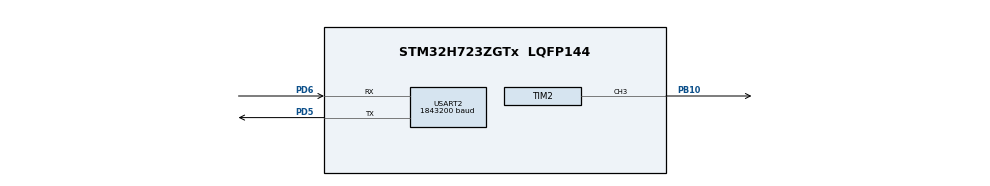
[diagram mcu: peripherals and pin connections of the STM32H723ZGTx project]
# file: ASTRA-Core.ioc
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CORTEX_M7.default_mode_Activation=1
Mcu.Family=STM32H7
Mcu.Name=STM32H723ZGTx
Mcu.Package=LQFP144
NUCLEO-H723ZG.BUTTON=1
NUCLEO-H723ZG.LD1=true
NUCLEO-H723ZG.LD2=true
NUCLEO-H723ZG.LD3=true
NUCLEO-H723ZG.VCP=true
NVIC.EXTI15_10_IRQn=true\:0\:0\:false\:false\:true\:false\:true\:true
NVIC.PriorityGroup=NVIC_PRIORITYGROUP_4
NVIC.USART2_IRQn=true\:0\:0\:false\:false\:true\:true\:true\:true
PA13(JTMS/SWDIO).GPIO_Label=SWDIO
PA13(JTMS/SWDIO).Signal=DEBUG_JTMS-SWDIO
PA14(JTCK/SWCLK).GPIO_Label=SWCLK
PA14(JTCK/SWCLK).Signal=DEBUG_JTCK-SWCLK
PB10.Signal=S_TIM2_CH3
PC14-OSC32_IN.Signal=RCC_OSC32_IN
PC15-OSC32_OUT.Signal=RCC_OSC32_OUT
PD5.Mode=Asynchronous
PD5.Signal=USART2_TX
PD6.Mode=Asynchronous
PD6.Signal=USART2_RX
PD8.Signal=USART3_TX
PD9.Signal=USART3_RX
ProjectManager.HeapSize=0x200
ProjectManager.StackSize=0x400
ProjectManager.TargetToolchain=STM32CubeIDE
RCC.ADCFreq_Value=608000000
RCC.APB1Freq_Value=75000000
RCC.APB2Freq_Value=75000000
RCC.APB3Freq_Value=75000000
RCC.APB4Freq_Value=75000000
RCC.CortexFreq_Value=300000000
RCC.D1PPRE=RCC_APB3_DIV2
RCC.D2PPRE1=RCC_APB1_DIV2
RCC.D2PPRE2=RCC_APB2_DIV2
RCC.D3PPRE=RCC_APB4_DIV2
RCC.DIVM1=4
RCC.DIVM2=1
RCC.DIVN1=18
RCC.DIVN2=19
RCC.DIVP1=1
RCC.DIVQ1=4
RCC.HCLKFreq_Value=150000000
RCC.HPRE=RCC_HCLK_DIV2
RCC.HSE_VALUE=8000000
RCC.PLLFRACN=6144
RCC.SYSCLKFreq_VALUE=300000000
RCC.SYSCLKSource=RCC_SYSCLKSOURCE_PLLCLK
RCC.USBCLockSelection=RCC_USBCLKSOURCE_HSI48
RCC.USBFreq_Value=48000000
SH.S_TIM2_CH3.0=TIM2_CH3,PWM Generation3 CH3
TIM2.Channel-PWM\ Generation3\ CH3=TIM_CHANNEL_3
TIM2.Period=3029
TIM2.Prescaler=149
TIM2.Pulse-PWM\ Generation3\ CH3=1500
USART2.BaudRate=1843200
USART2.VirtualMode-Asynchronous=VM_ASYNC
VP_MEMORYMAP_VS_MEMORYMAP.Mode=CurAppReg
VP_NUCLEO-H723ZG_VS_BSP_COMMON.Mode=COMMON
VP_TIM2_VS_ClockSourceINT.Mode=Internal
board=NUCLEO-H723ZG

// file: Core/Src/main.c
/* USER CODE BEGIN Header */
/**
  ******************************************************************************
  * @file           : main.c
  * @brief          : Main program body
  ******************************************************************************
  * @attention
  *
  * Copyright (c) 2026 STMicroelectronics.
  * All rights reserved.
  *
  * This software is licensed under terms that can be found in the LICENSE file
  * in the root directory of this software component.
  * If no LICENSE file comes with this software, it is provided AS-IS.
  *
  ******************************************************************************
  */
/* USER CODE END Header */
#include "main.h"
#include "tim.h"
#include "usart.h"
#include "gpio.h"

/* USER CODE BEGIN Includes */
#include "control.h"
#include "telemetry.h"
#include "flight_log.h"
#include "telem_playback.h"
#include "coast_sil.h"
#include "physics.h"
#include <string.h>

/* 1 = embedded CSV playback, 0 = USART2 flight telemetry */
#ifndef TELEM_SOURCE_PLAYBACK
#define TELEM_SOURCE_PLAYBACK  1
#endif
/* 1 = CSV to burnout then closed-loop coast, 0 = full CSV open-loop */
#ifndef TELEM_PLAYBACK_CLOSED_LOOP
#define TELEM_PLAYBACK_CLOSED_LOOP  1
#endif
/* Discrete PWM levels: 1 = continuous (off); >1 = N steps on [0°, 60°] */
#ifndef SERVO_DISCRETE_LEVELS
#define SERVO_DISCRETE_LEVELS  1U
#endif
/* 1 = boot sweep before main loop */
#ifndef SERVO_BOOT_SWEEP
#define SERVO_BOOT_SWEEP  0
#endif
/* Seconds for full SAFE→OPEN (0→60°); 0 = instant. Closing is always instant. */
#ifndef SERVO_OPEN_TIME_S
#define SERVO_OPEN_TIME_S  (0.4f)
#endif
/* Flash log window by fc_state (UART + playback). */
#ifndef FLIGHT_LOG_UART_STATE_START
#define FLIGHT_LOG_UART_STATE_START  ((uint8_t)TELEM_STATE_ACCELERATING)  /* 2 */
#endif
#ifndef FLIGHT_LOG_UART_STATE_STOP
#define FLIGHT_LOG_UART_STATE_STOP   ((uint8_t)TELEM_STATE_LANDED)    /* 3 */
#endif
/* USER CODE END Includes */

COM_InitTypeDef BspCOMInit;

/* USER CODE BEGIN PV */
#define huart_fc huart2

static control_t g_control;
static stub_telemetry_frame_t g_telem;
static stub_telemetry_frame_t g_telem_work;
static volatile uint8_t g_telem_ready;
static uint8_t g_log_active;
static uint8_t g_log_done;
#if TELEM_SOURCE_PLAYBACK
typedef enum {
    PLAYBACK_CSV = 0,
    PLAYBACK_COAST,
    PLAYBACK_DONE
} playback_phase_t;

static uint8_t g_playback_finished;
static playback_phase_t g_playback_phase;
static uint32_t g_burnout_idx;
static coast_sil_t g_coast_sil;
#endif
/* USER CODE END PV */

void SystemClock_Config(void);
static void MPU_Config(void);

/* USER CODE BEGIN 0 */
extern TIM_HandleTypeDef htim2;
_Static_assert(sizeof(stub_telemetry_frame_t) == 21u, "Telemetry frame must be 21 bytes");

/** Append only while START <= state < STOP; latch stop permanently. */
static void FlightLog_MaybeAppend(
    const stub_telemetry_frame_t *frame,
    const flight_state_t *st,
    const control_output_t *cmd)
{
    if (!g_log_done) {
        if (frame->state >= FLIGHT_LOG_UART_STATE_STOP) {
            if (g_log_active) {
                g_log_done = 1U;
            }
        } else if (frame->state >= FLIGHT_LOG_UART_STATE_START) {
            g_log_active = 1U;
            (void)flight_log_append(frame, st, cmd);
            if (flight_log_is_full()) {
                BSP_LED_On(LED_RED);
            }
        }
    }
}

/*
 * Servo mapping (sync with core/physics_utils.py):
 *   u=0 -> 0 deg (brakes retracted, safe)
 *   u=1 -> 60 deg (max brake)
 * PWM: SERVO_PWM_MIN @ 60 deg, SERVO_PWM_MAX @ 0 deg.
 */
#ifndef SERVO_PWM_MIN
#define SERVO_PWM_MIN  (960u)
#endif
#ifndef SERVO_PWM_MAX
#define SERVO_PWM_MAX  (1600u)
#endif
#ifndef SERVO_TIM_CHANNEL
#define SERVO_TIM_CHANNEL  TIM_CHANNEL_3
#endif

/** Round to nearest of SERVO_DISCRETE_LEVELS steps on [SAFE, OPEN]. */
#if SERVO_DISCRETE_LEVELS > 1U
static float Servo_DiscretizeAngleDeg(float angle_deg)
{
    const float span = SERVO_ANGLE_OPEN_DEG - SERVO_ANGLE_SAFE_DEG;
    const float step = span / (float)(SERVO_DISCRETE_LEVELS - 1U);
    uint32_t idx = (uint32_t)((angle_deg - SERVO_ANGLE_SAFE_DEG) / step + 0.5f);

    if (idx >= SERVO_DISCRETE_LEVELS) {
        idx = SERVO_DISCRETE_LEVELS - 1U;
    }
    return SERVO_ANGLE_SAFE_DEG + (float)idx * step;
}
#endif

static float Servo_SetAngleDeg(float angle_deg)
{
    static float s_angle = SERVO_ANGLE_SAFE_DEG;
    static uint32_t s_tick_ms;
    static uint8_t s_have_tick;

    if (angle_deg != angle_deg) { /* NaN */
        angle_deg = SERVO_ANGLE_SAFE_DEG;
    }
    /* SAFE=0 … OPEN=60 */
    angle_deg = clamp_f(angle_deg, SERVO_ANGLE_SAFE_DEG, SERVO_ANGLE_OPEN_DEG);

    {
        const uint32_t now = HAL_GetTick();
        if (!s_have_tick) {
            s_angle = angle_deg;
            s_tick_ms = now;
            s_have_tick = 1U;
        } else {
            const float dt = (float)(now - s_tick_ms) * 0.001f;
            s_tick_ms = now;
            if (angle_deg < s_angle) {
                /* Close immediately (safe retract). */
                s_angle = angle_deg;
            } else if (angle_deg > s_angle) {
                if (SERVO_OPEN_TIME_S <= 0.0f || dt <= 0.0f) {
                    s_angle = angle_deg;
                } else {
                    const float span = SERVO_ANGLE_OPEN_DEG - SERVO_ANGLE_SAFE_DEG;
                    const float max_step = (span / SERVO_OPEN_TIME_S) * dt;
                    const float need = angle_deg - s_angle;
                    s_angle += (need < max_step) ? need : max_step;
                }
            }
        }
        angle_deg = s_angle;
    }

    {
        float pwm_angle = angle_deg;
#if SERVO_DISCRETE_LEVELS > 1U
        pwm_angle = Servo_DiscretizeAngleDeg(pwm_angle);
#endif
        /* 0° → PWM_MAX, 60° → PWM_MIN */
        const float span = SERVO_ANGLE_OPEN_DEG - SERVO_ANGLE_SAFE_DEG;
        const float open_frac = (pwm_angle - SERVO_ANGLE_SAFE_DEG) / span;
        uint32_t pulse = (uint32_t)(
            (float)SERVO_PWM_MAX
            - open_frac * (float)(SERVO_PWM_MAX - SERVO_PWM_MIN));
        __HAL_TIM_SET_COMPARE(&htim2, SERVO_TIM_CHANNEL, pulse);
        return pwm_angle;
    }
}

#if !TELEM_SOURCE_PLAYBACK
static void Telemetry_ClearRxErrors(void)
{
    __HAL_UART_FLUSH_DRREGISTER(&huart_fc);
    __HAL_UART_CLEAR_OREFLAG(&huart_fc);
    __HAL_UART_CLEAR_NEFLAG(&huart_fc);
    __HAL_UART_CLEAR_FEFLAG(&huart_fc);
    huart_fc.ErrorCode = HAL_UART_ERROR_NONE;
}

static void Telemetry_DisableRx(void)
{
    (void)HAL_UART_AbortReceive_IT(&huart_fc);
    CLEAR_BIT(huart_fc.Instance->CR1, USART_CR1_RE);
    Telemetry_ClearRxErrors();
}

static void Telemetry_StartRx(stub_telemetry_frame_t *dst)
{
    (void)HAL_UART_AbortReceive_IT(&huart_fc);
    Telemetry_ClearRxErrors();
    SET_BIT(huart_fc.Instance->CR1, USART_CR1_RE);
    if (HAL_UART_Receive_IT(&huart_fc, (uint8_t *)dst, TELEMETRY_FRAME_SIZE) != HAL_OK) {
        Error_Handler();
    }
}

static void OnTelemetryFrameReceived(void)
{
    g_telem_ready = 1;
}
#else
static void Playback_Finish(void)
{
    g_playback_finished = 1U;
    g_playback_phase = PLAYBACK_DONE;
    if (flight_log_flush() != 0) {
        BSP_LED_On(LED_RED);
    } else {
        BSP_LED_On(LED_GREEN);
    }
}

static void PlantState_ToTelem(const flight_state_t *st, stub_telemetry_frame_t *frame)
{
    frame->state = (uint8_t)TELEM_STATE_FREE_FLIGHT;
    frame->timeMs = (uint32_t)(st->time_s * 1000.0f);
    frame->posZ = st->position_z;
    frame->velZ = st->velocity_z;
    frame->gpsSpeed = st->velocity_lateral;
    frame->gpsCourse = 0.0f;
}

static void Telemetry_PlaybackFeed(void)
{
    if (g_playback_finished) {
        return;
    }

#if TELEM_PLAYBACK_CLOSED_LOOP
    if (g_playback_phase == PLAYBACK_CSV) {
        if (telem_playback_next(&g_telem) == 0U) {
            Playback_Finish();
            return;
        }
        g_telem_ready = 1;
        return;
    }

    if (g_playback_phase == PLAYBACK_COAST) {
        flight_state_t st;
        control_output_t cmd;
        if (coast_sil_step(&g_coast_sil, &g_control, &st, &cmd) == 0U) {
            Playback_Finish();
            return;
        }
        PlantState_ToTelem(&st, &g_telem_work);
        cmd.servo_angle_deg = Servo_SetAngleDeg(
            cmd.active ? cmd.servo_angle_deg : SERVO_ANGLE_SAFE_DEG);
        {
            const float span = SERVO_ANGLE_OPEN_DEG - SERVO_ANGLE_SAFE_DEG;
            g_coast_sil.u = (cmd.servo_angle_deg - SERVO_ANGLE_SAFE_DEG) / span;
        }
        FlightLog_MaybeAppend(&g_telem_work, &st, &cmd);
        return;
    }
#else
    if (telem_playback_next(&g_telem) == 0U) {
        Playback_Finish();
        return;
    }
    g_telem_ready = 1;
#endif
}
#endif
/* USER CODE END 0 */

int main(void)
{

  /* MPU Configuration--------------------------------------------------------*/
  MPU_Config();

  /* MCU Configuration--------------------------------------------------------*/

  /* Reset of all peripherals, Initializes the Flash interface and the Systick. */
  HAL_Init();

  /* Configure the system clock */
  SystemClock_Config();

  /* Initialize all configured peripherals */
  MX_GPIO_Init();
  MX_TIM2_Init();
  MX_USART2_UART_Init();
  /* USER CODE BEGIN 2 */
#if !TELEM_SOURCE_PLAYBACK
  Telemetry_DisableRx();
#endif
  HAL_TIM_PWM_Start(&htim2, SERVO_TIM_CHANNEL);

  control_init(&g_control);
  /* Model params: model_params_default() in physics.c (mass 12.57 kg, Cd 0.42,
   * BODY_CROSS_SECTION_M2). Override here only for experiments. */
  g_control.pd.params.target_apogee = 1400.0f;
  g_control.pd.params.kp = 0.08f;
  g_control.pd.params.kd = 0.0005f;
  g_control.pd.params.error_deadband = 10.0f;
  g_control.predictor.solver = SOLVER_EULER;
  g_control.predictor.dt = 0.01f;

  BSP_LED_Init(LED_GREEN);
  BSP_LED_Init(LED_YELLOW);
  BSP_LED_Init(LED_RED);

#if TELEM_SOURCE_PLAYBACK
  if (flight_log_begin_staging() != 0) {
    Error_Handler();
  }
  telem_playback_reset();
  g_playback_finished = 0U;
  g_playback_phase = PLAYBACK_CSV;
  g_burnout_idx = telem_playback_burnout_index();
  g_log_active = 0U;
  g_log_done = 0U;
#if TELEM_PLAYBACK_CLOSED_LOOP
  if (g_burnout_idx >= TELEM_PLAYBACK_FRAME_COUNT) {
    Error_Handler();
  }
#endif
#else
  if (flight_log_boot() != 0) {
    Error_Handler();
  }
  g_log_active = 0U;
  g_log_done = 0U;
  Telemetry_StartRx(&g_telem);
#endif
  /* USER CODE END 2 */

  /* Initialize USER push-button, will be used to trigger an interrupt each time it's pressed.*/
  BSP_PB_Init(BUTTON_USER, BUTTON_MODE_EXTI);

  /* Infinite loop */
  /* USER CODE BEGIN WHILE */
#if SERVO_BOOT_SWEEP
  Servo_SetAngleDeg(SERVO_ANGLE_SAFE_DEG);
  BSP_LED_Toggle(LED_GREEN);
  HAL_Delay(1000);
//  Servo_SetAngleDeg(12.0f);
//  BSP_LED_Toggle(LED_GREEN);
//  HAL_Delay(1000);
//  Servo_SetAngleDeg(24.0f);
//  BSP_LED_Toggle(LED_GREEN);
//  HAL_Delay(1000);
  Servo_SetAngleDeg(36.0f);
  BSP_LED_Toggle(LED_GREEN);
  HAL_Delay(1000);
//  Servo_SetAngleDeg(48.0f);
//  BSP_LED_Toggle(LED_GREEN);
//  HAL_Delay(1000);
//  Servo_SetAngleDeg(SERVO_ANGLE_OPEN_DEG);
//  BSP_LED_Toggle(LED_GREEN);
//  HAL_Delay(1000);
  Servo_SetAngleDeg(SERVO_ANGLE_SAFE_DEG);
  BSP_LED_Off(LED_GREEN);
#else
  Servo_SetAngleDeg(SERVO_ANGLE_SAFE_DEG);
#endif

  BSP_LED_On(LED_YELLOW);

  while (1)
  {
#if TELEM_SOURCE_PLAYBACK
    Telemetry_PlaybackFeed();
#endif

    if (g_telem_ready) {
        g_telem_ready = 0;
        memcpy(&g_telem_work, &g_telem, TELEMETRY_FRAME_SIZE);
#if !TELEM_SOURCE_PLAYBACK
        BSP_LED_Toggle(LED_GREEN);
        Telemetry_StartRx(&g_telem);
#endif

        flight_state_t st;
        control_output_t cmd = telemetry_run_control(&g_control, &g_telem_work, &st);
        cmd.servo_angle_deg = Servo_SetAngleDeg(
            cmd.active ? cmd.servo_angle_deg : SERVO_ANGLE_SAFE_DEG);

        FlightLog_MaybeAppend(&g_telem_work, &st, &cmd);

#if TELEM_SOURCE_PLAYBACK && TELEM_PLAYBACK_CLOSED_LOOP
        if (g_playback_phase == PLAYBACK_CSV && g_control.armed) {
            coast_sil_init(&g_coast_sil, &st, cmd.control_u, COAST_SIL_MAX_STEPS_DEFAULT);
            g_playback_phase = PLAYBACK_COAST;
        }
#endif
    }
    /* USER CODE END WHILE */

  }
}

void SystemClock_Config(void)
{
  RCC_OscInitTypeDef RCC_OscInitStruct = {0};
  RCC_ClkInitTypeDef RCC_ClkInitStruct = {0};

  /** Supply configuration update enable
  */
  HAL_PWREx_ConfigSupply(PWR_LDO_SUPPLY);

  /** Configure the main internal regulator output voltage
  */
  __HAL_PWR_VOLTAGESCALING_CONFIG(PWR_REGULATOR_VOLTAGE_SCALE2);

  while(!__HAL_PWR_GET_FLAG(PWR_FLAG_VOSRDY)) {}

  /** Initializes the RCC Oscillators according to the specified parameters
  * in the RCC_OscInitTypeDef structure.
  */
  RCC_OscInitStruct.OscillatorType = RCC_OSCILLATORTYPE_HSI;
  RCC_OscInitStruct.HSIState = RCC_HSI_DIV1;
  RCC_OscInitStruct.HSICalibrationValue = 64;
  RCC_OscInitStruct.PLL.PLLState = RCC_PLL_ON;
  RCC_OscInitStruct.PLL.PLLSource = RCC_PLLSOURCE_HSI;
  RCC_OscInitStruct.PLL.PLLM = 4;
  RCC_OscInitStruct.PLL.PLLN = 18;
  RCC_OscInitStruct.PLL.PLLP = 1;
  RCC_OscInitStruct.PLL.PLLQ = 4;
  RCC_OscInitStruct.PLL.PLLR = 2;
  RCC_OscInitStruct.PLL.PLLRGE = RCC_PLL1VCIRANGE_3;
  RCC_OscInitStruct.PLL.PLLVCOSEL = RCC_PLL1VCOWIDE;
  RCC_OscInitStruct.PLL.PLLFRACN = 6144;
  if (HAL_RCC_OscConfig(&RCC_OscInitStruct) != HAL_OK)
  {
    Error_Handler();
  }

  /** Initializes the CPU, AHB and APB buses clocks
  */
  RCC_ClkInitStruct.ClockType = RCC_CLOCKTYPE_HCLK|RCC_CLOCKTYPE_SYSCLK
                              |RCC_CLOCKTYPE_PCLK1|RCC_CLOCKTYPE_PCLK2
                              |RCC_CLOCKTYPE_D3PCLK1|RCC_CLOCKTYPE_D1PCLK1;
  RCC_ClkInitStruct.SYSCLKSource = RCC_SYSCLKSOURCE_PLLCLK;
  RCC_ClkInitStruct.SYSCLKDivider = RCC_SYSCLK_DIV1;
  RCC_ClkInitStruct.AHBCLKDivider = RCC_HCLK_DIV2;
  RCC_ClkInitStruct.APB3CLKDivider = RCC_APB3_DIV2;
  RCC_ClkInitStruct.APB1CLKDivider = RCC_APB1_DIV2;
  RCC_ClkInitStruct.APB2CLKDivider = RCC_APB2_DIV2;
  RCC_ClkInitStruct.APB4CLKDivider = RCC_APB4_DIV2;

  if (HAL_RCC_ClockConfig(&RCC_ClkInitStruct, FLASH_LATENCY_2) != HAL_OK)
  {
    Error_Handler();
  }
}

/* USER CODE BEGIN 4 */
#if !TELEM_SOURCE_PLAYBACK
void HAL_UART_RxCpltCallback(UART_HandleTypeDef *huart)
{
    if (huart == &huart_fc) {
        OnTelemetryFrameReceived();
    }
}

void HAL_UART_ErrorCallback(UART_HandleTypeDef *huart)
{
    if (huart == &huart_fc) {
        Telemetry_StartRx(&g_telem);
    }
}
#endif

/* USER CODE END 4 */

 /* MPU Configuration */

void MPU_Config(void)
{
  MPU_Region_InitTypeDef MPU_InitStruct = {0};

  /* Disables the MPU */
  HAL_MPU_Disable();

  /** Initializes and configures the Region and the memory to be protected
  */
  MPU_InitStruct.Enable = MPU_REGION_ENABLE;
  MPU_InitStruct.Number = MPU_REGION_NUMBER0;
  MPU_InitStruct.BaseAddress = 0x0;
  MPU_InitStruct.Size = MPU_REGION_SIZE_4GB;
  MPU_InitStruct.SubRegionDisable = 0x87;
  MPU_InitStruct.TypeExtField = MPU_TEX_LEVEL0;
  MPU_InitStruct.AccessPermission = MPU_REGION_NO_ACCESS;
  MPU_InitStruct.DisableExec = MPU_INSTRUCTION_ACCESS_DISABLE;
  MPU_InitStruct.IsShareable = MPU_ACCESS_SHAREABLE;
  MPU_InitStruct.IsCacheable = MPU_ACCESS_NOT_CACHEABLE;
  MPU_InitStruct.IsBufferable = MPU_ACCESS_NOT_BUFFERABLE;

  HAL_MPU_ConfigRegion(&MPU_InitStruct);
  /* Enables the MPU */
  HAL_MPU_Enable(MPU_PRIVILEGED_DEFAULT);

}

void Error_Handler(void)
{
  __disable_irq();
  while (1)
  {
  }
}
